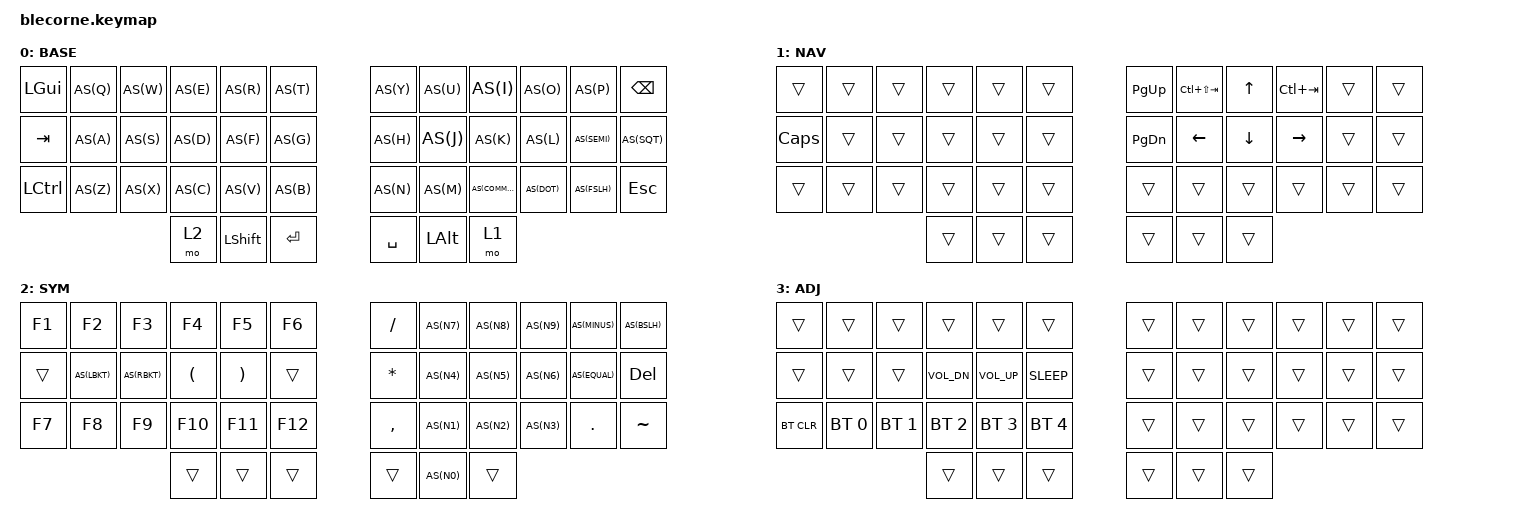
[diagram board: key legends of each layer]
/*
 * Copyright (c) 2020 The ZMK Contributors
 * SPDX-License-Identifier: MIT
 */

#include <behaviors.dtsi>
#include <dt-bindings/zmk/keys.h>
#include <dt-bindings/zmk/bt.h>
#include <dt-bindings/zmk/outputs.h>

/ {
    chosen {
        zmk,physical-layout = &foostan_corne_6col_layout;
        // zmk,physical-layout = &foostan_corne_5col_layout;
    };
};

#define BASE 0
#define NAV  1
#define SYM  2
#define ADJ  3
#define AS(keycode) &as LS(keycode) keycode     // Autoshift Macro

/ {
    conditional_layers {
        compatible = "zmk,conditional-layers";
        tri_layer {
            if-layers = <1 2>;
            then-layer = <3>;
        };
    };

    behaviors {
      as: auto_shift {
          compatible = "zmk,behavior-hold-tap";
          #binding-cells = <2>;
          tapping-term-ms = <200>;
          quick-tap-ms = <0>;
          flavor = "tap-preferred";
          bindings = <&kp>, <&kp>;
      };
    };

    keymap {
            compatible = "zmk,keymap";

            base {
                display-name = "BASE";
                bindings = <
&kp LGUI    AS(Q)   AS(W)   AS(E)   AS(R)       AS(T)       AS(Y)      AS(U)     AS(I)     AS(O)   AS(P)     &kp BSPC
&kp TAB     AS(A)   AS(S)   AS(D)   AS(F)       AS(G)       AS(H)      AS(J)     AS(K)     AS(L)   AS(SEMI)  AS(SQT)
&kp LCTRL   AS(Z)   AS(X)   AS(C)   AS(V)       AS(B)       AS(N)      AS(M)     AS(COMMA) AS(DOT) AS(FSLH)  &kp ESC
                            &mo 2   &kp LSHFT   &kp ENTER   &kp SPACE  &kp LALT  &mo 1
                >;
            };

            nav {
                display-name = "NAV";
                bindings = <
&trans      &trans    &trans    &trans    &trans    &trans    &kp PG_UP  &kp LC(LS(TAB))  &kp UP    &kp LC(TAB)  &trans  &trans
&kp CAPS    &trans    &trans    &trans    &trans    &trans    &kp PG_DN  &kp LEFT         &kp DOWN  &kp RIGHT    &trans  &trans
&trans      &trans    &trans    &trans    &trans    &trans    &trans     &trans           &trans    &trans       &trans  &trans
                                &trans    &trans    &trans    &trans     &trans           &trans
                >;
            };

            sym {
                display-name = "SYM";
                bindings = <
&kp F1    &kp F2    &kp F3    &kp F4    &kp F5    &kp F6      &kp SLASH     AS(N7)  AS(N8)   AS(N9)   AS(MINUS)   AS(BSLH)
&trans    AS(LBKT)  AS(RBKT)  &kp LPAR  &kp RPAR  &trans      &kp ASTERISK  AS(N4)  AS(N5)   AS(N6)   AS(EQUAL)   &kp DEL
&kp F7    &kp F8    &kp F9    &kp F10   &kp F11   &kp F12     &kp COMMA     AS(N1)  AS(N2)   AS(N3)   &kp DOT     &kp TILDE
                              &trans    &trans    &trans      &trans        AS(N0)  &trans
                >;
            };
            adj {
                display-name = "ADJ";
                bindings = <
&trans      &trans        &trans        &trans        &trans        &trans          &trans    &trans    &trans    &trans    &trans    &trans
&trans      &trans        &trans        &kp C_VOL_DN  &kp C_VOL_UP  &kp C_SLEEP     &trans    &trans    &trans    &trans    &trans    &trans
&bt BT_CLR  &bt BT_SEL 0  &bt BT_SEL 1  &bt BT_SEL 2  &bt BT_SEL 3  &bt BT_SEL 4    &trans    &trans    &trans    &trans    &trans    &trans
                                        &trans        &trans        &trans          &trans    &trans    &trans
                >;
            };
            extra_1 {
                    status = "reserved";
            };

            extra_2 {
                    status = "reserved";
            };

            extra_3 {
                    status = "reserved";
            };
    };
};
